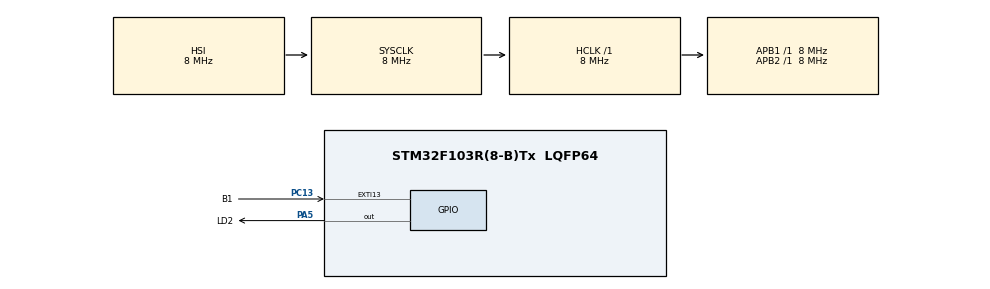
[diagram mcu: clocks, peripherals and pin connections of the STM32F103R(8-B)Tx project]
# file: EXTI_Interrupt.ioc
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Mcu.Family=STM32F1
Mcu.Name=STM32F103R(8-B)Tx
Mcu.Package=LQFP64
NVIC.EXTI15_10_IRQn=true\:0\:0\:false\:false\:true\:false\:true\:true
NVIC.PriorityGroup=NVIC_PRIORITYGROUP_4
PA5.GPIO_Label=LD2
PA5.Signal=GPIO_Output
PC13.GPIO_Label=B1
PC13.GPIO_Mode=GPIO_MODE_IT_FALLING
PC13.GPIO_PuPd=GPIO_PULLUP
PC13.Signal=GPIO_EXTI13
ProjectManager.HeapSize=0x200
ProjectManager.StackSize=0x400
ProjectManager.TargetToolchain=STM32CubeIDE
RCC.AHBFreq_Value=8000000
RCC.APB1Freq_Value=8000000
RCC.APB1TimFreq_Value=8000000
RCC.APB2Freq_Value=8000000
RCC.APB2TimFreq_Value=8000000
RCC.HCLKFreq_Value=8000000
RCC.SYSCLKFreq_VALUE=8000000
RCC.USBFreq_Value=8000000
VP_SYS_VS_ND.Mode=No_Debug
board=custom

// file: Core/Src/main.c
/* USER CODE BEGIN Header */
/**
  ******************************************************************************
  * @file           : main.c
  * @brief          : 04_EXTI_Interrupt - button interrupt with EXTI
  ******************************************************************************
  * @attention
  *
  * Copyright (c) 2026 STMicroelectronics.
  * All rights reserved.
  *
  ******************************************************************************
  */
/* USER CODE END Header */

#include "main.h"

/* USER CODE BEGIN PV */
extern volatile uint8_t btn_pressed;
/* USER CODE END PV */

void SystemClock_Config(void);
static void MX_GPIO_Init(void);

int main(void)
{

  HAL_Init();

  SystemClock_Config();

  MX_GPIO_Init();

  /* Infinite loop */
  /* USER CODE BEGIN WHILE */
  while (1)
  {
    if (btn_pressed)
    {
      HAL_GPIO_TogglePin(LD2_GPIO_Port, LD2_Pin);
      btn_pressed = 0;
    }
    /* USER CODE END WHILE */

  }
}

void SystemClock_Config(void)
{
  RCC_OscInitTypeDef RCC_OscInitStruct = {0};
  RCC_ClkInitTypeDef RCC_ClkInitStruct = {0};

  /** Initializes the RCC Oscillators according to the specified parameters
  */
  RCC_OscInitStruct.OscillatorType = RCC_OSCILLATORTYPE_HSI;
  RCC_OscInitStruct.HSIState = RCC_HSI_ON;
  RCC_OscInitStruct.HSICalibrationValue = RCC_HSICALIBRATION_DEFAULT;
  RCC_OscInitStruct.PLL.PLLState = RCC_PLL_NONE;
  if (HAL_RCC_OscConfig(&RCC_OscInitStruct) != HAL_OK)
  {
    Error_Handler();
  }

  /** Initializes the CPU, AHB and APB buses clocks
  */
  RCC_ClkInitStruct.ClockType = RCC_CLOCKTYPE_HCLK|RCC_CLOCKTYPE_SYSCLK
                              |RCC_CLOCKTYPE_PCLK1|RCC_CLOCKTYPE_PCLK2;
  RCC_ClkInitStruct.SYSCLKSource = RCC_SYSCLKSOURCE_HSI;
  RCC_ClkInitStruct.AHBCLKDivider = RCC_SYSCLK_DIV1;
  RCC_ClkInitStruct.APB1CLKDivider = RCC_HCLK_DIV1;
  RCC_ClkInitStruct.APB2CLKDivider = RCC_HCLK_DIV1;

  if (HAL_RCC_ClockConfig(&RCC_ClkInitStruct, FLASH_LATENCY_0) != HAL_OK)
  {
    Error_Handler();
  }
}

static void MX_GPIO_Init(void)
{
  GPIO_InitTypeDef GPIO_InitStruct = {0};

  /* GPIO Ports Clock Enable */
  __HAL_RCC_GPIOC_CLK_ENABLE();
  __HAL_RCC_GPIOA_CLK_ENABLE();
  __HAL_RCC_AFIO_CLK_ENABLE();

  /*Configure GPIO pin Output Level */
  HAL_GPIO_WritePin(LD2_GPIO_Port, LD2_Pin, GPIO_PIN_RESET);

  /*Configure GPIO pin : LD2_Pin */
  GPIO_InitStruct.Pin = LD2_Pin;
  GPIO_InitStruct.Mode = GPIO_MODE_OUTPUT_PP;
  GPIO_InitStruct.Pull = GPIO_NOPULL;
  GPIO_InitStruct.Speed = GPIO_SPEED_FREQ_LOW;
  HAL_GPIO_Init(LD2_GPIO_Port, &GPIO_InitStruct);

  /*Configure GPIO pin : PC13 - B1 user button, EXTI on falling edge */
  GPIO_InitStruct.Pin = B1_Pin;
  GPIO_InitStruct.Mode = GPIO_MODE_IT_FALLING;
  GPIO_InitStruct.Pull = GPIO_PULLUP;
  HAL_GPIO_Init(B1_GPIO_Port, &GPIO_InitStruct);

  /* EXTI interrupt mode config */
  HAL_NVIC_SetPriority(EXTI15_10_IRQn, 0, 0);
  HAL_NVIC_EnableIRQ(EXTI15_10_IRQn);
}

void Error_Handler(void)
{
  __disable_irq();
  while (1)
  {
  }
}

#ifdef USE_FULL_ASSERT
/**
  * @brief  Reports the name of the source file and the source line number
  * @param  file: pointer to the source file name
  * @param  line: assert_param error line source number
  * @retval None
  */
void assert_failed(uint8_t *file, uint32_t line)
{
  /* USER CODE BEGIN 6 */
  (void)file;
  (void)line;
  /* USER CODE END 6 */
}
#endif /* USE_FULL_ASSERT */
